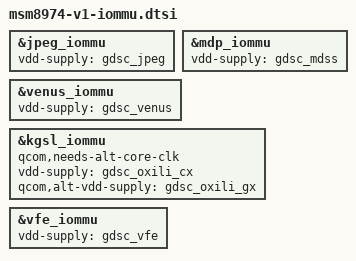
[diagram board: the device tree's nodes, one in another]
/* Copyright (c) 2012-2013, The Linux Foundation. All rights reserved.
 *
 * This program is free software; you can redistribute it and/or modify
 * it under the terms of the GNU General Public License version 2 and
 * only version 2 as published by the Free Software Foundation.
 *
 * This program is distributed in the hope that it will be useful,
 * but WITHOUT ANY WARRANTY; without even the implied warranty of
 * MERCHANTABILITY or FITNESS FOR A PARTICULAR PURPOSE.  See the
 * GNU General Public License for more details.
 */

#include "msm-iommu-v1.dtsi"

&jpeg_iommu {
	status = "ok";
	vdd-supply = <&gdsc_jpeg>;
};

&mdp_iommu {
	status = "ok";
	vdd-supply = <&gdsc_mdss>;
};

&venus_iommu {
	status = "ok";
	vdd-supply = <&gdsc_venus>;
};

&kgsl_iommu {
	status = "ok";
	qcom,needs-alt-core-clk;
	vdd-supply = <&gdsc_oxili_cx>;
	qcom,alt-vdd-supply = <&gdsc_oxili_gx>;
};

&vfe_iommu {
	status = "ok";
	vdd-supply = <&gdsc_vfe>;
};
